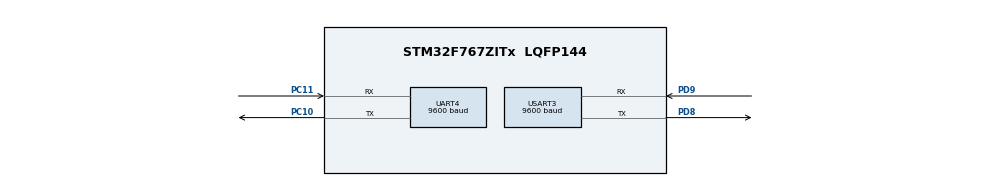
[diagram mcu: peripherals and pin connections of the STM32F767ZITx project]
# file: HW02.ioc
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Mcu.Family=STM32F7
Mcu.Name=STM32F767ZITx
Mcu.Package=LQFP144
NVIC.PriorityGroup=NVIC_PRIORITYGROUP_4
PC10.Mode=Asynchronous
PC10.Signal=UART4_TX
PC11.Mode=Asynchronous
PC11.Signal=UART4_RX
PD8.Mode=Asynchronous
PD8.Signal=USART3_TX
PD9.Mode=Asynchronous
PD9.Signal=USART3_RX
ProjectManager.HeapSize=0x200
ProjectManager.StackSize=0x400
ProjectManager.TargetToolchain=MDK-ARM V5.27
RCC.HSE_VALUE=25000000
RCC.HSI_VALUE=16000000
RCC.LSE_VALUE=32768
RCC.USBFreq_Value=96000000
RCC.VCOOutputFreq_Value=192000000
UART4.BaudRate=9600
USART3.BaudRate=9600
USART3.VirtualMode-Asynchronous=VM_ASYNC
board=custom

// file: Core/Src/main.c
/* USER CODE BEGIN Header */
/**
  ******************************************************************************
  * @file           : main.c
  * @brief          : Main program body
  ******************************************************************************
  * @attention
  *
  * <h2><center>&copy; Copyright (c) 2020 STMicroelectronics.
  * All rights reserved.</center></h2>
  *
  * This software component is licensed by ST under BSD 3-Clause license,
  * the "License"; You may not use this file except in compliance with the
  * License. You may obtain a copy of the License at:
  *                        opensource.org/licenses/BSD-3-Clause
  *
  ******************************************************************************
  */
/* USER CODE END Header */
#include "main.h"
#include "usart.h"
#include "gpio.h"

void SystemClock_Config(void);

int main(void)
{

  /* MCU Configuration--------------------------------------------------------*/

  /* Reset of all peripherals, Initializes the Flash interface and the Systick. */
  HAL_Init();

  /* Configure the system clock */
  SystemClock_Config();

  /* Initialize all configured peripherals */
  MX_GPIO_Init();
  MX_UART4_Init();
  MX_USART3_UART_Init();

  /* Infinite loop */
  /* USER CODE BEGIN WHILE */
  while (1)
  {
		HAL_UART_Transmit(&huart4, (uint8_t *)"27P", 3, 500);
		HAL_UART_Transmit(&huart3, (uint8_t *)"27P", 3, 500);

		HAL_Delay(500);

    /* USER CODE END WHILE */

  }
}

void SystemClock_Config(void)
{
  RCC_OscInitTypeDef RCC_OscInitStruct = {0};
  RCC_ClkInitTypeDef RCC_ClkInitStruct = {0};
  RCC_PeriphCLKInitTypeDef PeriphClkInitStruct = {0};

  /** Configure the main internal regulator output voltage
  */
  __HAL_RCC_PWR_CLK_ENABLE();
  __HAL_PWR_VOLTAGESCALING_CONFIG(PWR_REGULATOR_VOLTAGE_SCALE3);
  /** Initializes the RCC Oscillators according to the specified parameters
  * in the RCC_OscInitTypeDef structure.
  */
  RCC_OscInitStruct.OscillatorType = RCC_OSCILLATORTYPE_HSI;
  RCC_OscInitStruct.HSIState = RCC_HSI_ON;
  RCC_OscInitStruct.HSICalibrationValue = RCC_HSICALIBRATION_DEFAULT;
  RCC_OscInitStruct.PLL.PLLState = RCC_PLL_NONE;
  if (HAL_RCC_OscConfig(&RCC_OscInitStruct) != HAL_OK)
  {
    Error_Handler();
  }
  /** Initializes the CPU, AHB and APB buses clocks
  */
  RCC_ClkInitStruct.ClockType = RCC_CLOCKTYPE_HCLK|RCC_CLOCKTYPE_SYSCLK
                              |RCC_CLOCKTYPE_PCLK1|RCC_CLOCKTYPE_PCLK2;
  RCC_ClkInitStruct.SYSCLKSource = RCC_SYSCLKSOURCE_HSI;
  RCC_ClkInitStruct.AHBCLKDivider = RCC_SYSCLK_DIV1;
  RCC_ClkInitStruct.APB1CLKDivider = RCC_HCLK_DIV1;
  RCC_ClkInitStruct.APB2CLKDivider = RCC_HCLK_DIV1;

  if (HAL_RCC_ClockConfig(&RCC_ClkInitStruct, FLASH_LATENCY_0) != HAL_OK)
  {
    Error_Handler();
  }
  PeriphClkInitStruct.PeriphClockSelection = RCC_PERIPHCLK_USART3|RCC_PERIPHCLK_UART4;
  PeriphClkInitStruct.Usart3ClockSelection = RCC_USART3CLKSOURCE_PCLK1;
  PeriphClkInitStruct.Uart4ClockSelection = RCC_UART4CLKSOURCE_PCLK1;
  if (HAL_RCCEx_PeriphCLKConfig(&PeriphClkInitStruct) != HAL_OK)
  {
    Error_Handler();
  }
}

void Error_Handler(void)
{
}

/************************ (C) COPYRIGHT STMicroelectronics *****END OF FILE****/
